# nrf54l15_enga_application register map
Vendor: Nordic Semiconductor; Series: nrf54l; File version: 1
CPU: CM33 r0p4, little endian, MPU, FPU, 3 interrupt priority bits, 270 interrupts, 4 SAU regions
Registers are 32-bit, read-write, reset 0x0 unless marked. A register's access mark holds for its fields unless they carry their own. Offsets are from the block's base; [hi:lo] are bit positions; lines under a group give offsets from that group; {n}, {i} and the like mark numbered series.

## GLOBAL_GLITCHDET_S — Voltage glitch detectors
Base 0x5004B000
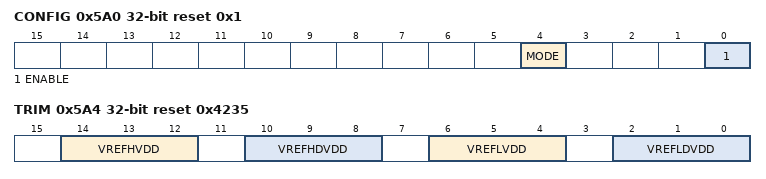
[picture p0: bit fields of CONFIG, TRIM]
0x5A0 CONFIG reset 0x1 — Configuration for glitch detector
  [4] MODE — Glitch detector mode
    0=High pass filter mode; 1=Cap divider mode
  [0] ENABLE — Enable glitch detector
    0=Disable glitch detector; 1=Enable glitch detector
0x5A4 TRIM reset 0x4235 — Trim configuration for glitch detector
  [14:12] VREFHVDD — Voltage trimming value for VREFH_VDD
    0=1V150 (0.150 V); 1=1V175 (0.175 V); 2=1V200 (1.200 V); 3=1V225 (1.225 V); 4=1V250 (1.250 V); 5=1V275 (1.275 V); 6=1V300 (1.300 V); 7=1V325 (1.325 V)
  [10:8] VREFHDVDD — Voltage trimming value for VREFH_DVDD
    0=0V950 (0.950 V); 1=0V975 (0.975 V); 2=1V000 (1.000 V); 3=1V025 (1.025 V); 4=1V050 (1.050 V); 5=1V075 (1.075 V); 6=1V100 (1.100 V); 7=1V125 (1.125 V)
  [6:4] VREFLVDD — Voltage trimming value for VREFL_VDD
    0=0V425 (0.425 V); 1=0V450 (0.450 V); 2=0V475 (0.475 V); 3=0V500 (0.500 V); 4=0V525 (0.525 V); 5=0V550 (0.550 V); 6=0V575 (0.575 V); 7=0V600 (0.600 V)
  [2:0] VREFLDVDD — Voltage trimming value for VREFL_DVDD
    0=0V675 (0.675 V); 1=0V700 (0.700 V); 2=0V725 (0.725 V); 3=0V750 (0.750 V); 4=0V775 (0.775 V); 5=0V800 (0.800 V); 6=0V825 (0.825 V); 7=0V850 (0.850 V)
0x5B0 DFT group — Unspecified
  0x00 ATB0CONFIG — Analog Test Bus 0 (ATB0) configuration
    [2:0] SELMUX — Select multiplexer for ATB0
      0=HiZ (High impedance); 1=VDDDIV (Measure/Force VDD_DIV voltage from external); 2=VDDDIG0V9 (Measure/Force VDD_DIG_0V9 voltage from external); 3=VSS; 4=GLITCHSRVDD3V0 (Internal signal - GLITCH_SR_VDD_3V0)
  0x04 ATB1CONFIG — Analog Test Bus 1 (ATB1) configuration
    [2:0] SELMUX — Select multiplexer for ATB1
      0=HiZ (High impedance); 1=VREFHVDD (Measure VREFH_VDD voltage); 2=VREFLVDD (Measure VREFL_VDD voltage); 3=VREFHDAVDD (Measure VREFH_DVDD voltage); 4=VREFLDVDD (Measure VREFL_DVDD voltage); 5=GLITCHSRDVDD3V0 (Internal signal - GLITCH_SR_DVDD_3V0)
  0x08 ATB2CONFIG — Analog Test Bus 2 (ATB2) configuration
    [1:0] SELMUX — Select multiplexer for ATB2
      0=HiZ (High impedance); 1=VTAMPORDVDD3V0 (Internal signal - VTAMP_OR_DVDD_3V0); 2=VTAMPORVDD3V0 (Internal signal - VTAMP_OR_VDD_3V0); 3=GLITCHNINT3V0 (Internal signal - GLITCH_N_INT_3V0)

## GLOBAL_GPIOHSPADCTRL_NS — GPIO high-speed pad control 0
Base 0x40050400
Same registers: GLOBAL_GPIOHSPADCTRL_S 0x50050400
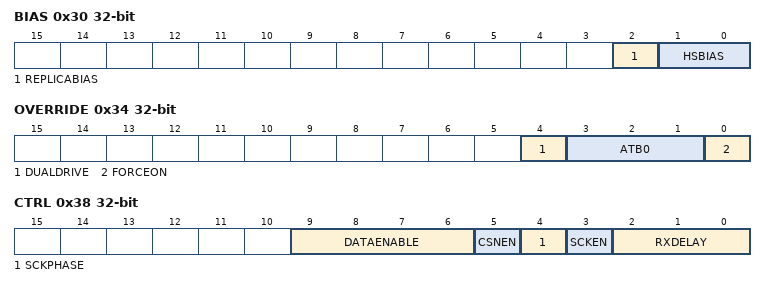
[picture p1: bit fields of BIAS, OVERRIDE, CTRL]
0x30 BIAS — Bias control
  [2] REPLICABIAS — Bias setting for replica pad
  [1:0] HSBIAS — Bias setting for high-speed pad
0x34 OVERRIDE — Override control
  [4] DUALDRIVE — Drive pad from both high-speed pad and regular pad (when highspeed is enabled)
  [3:1] ATB0 — ATB0 settings
    7=BiasTrim (Unspecified); 6=BiasSupply (Unspecified); 5=BiasPTAT (Unspecified)
  [0] FORCEON
0x38 CTRL — HS pad control register
  [9:6] DATAENABLE — Enable re-clocking for data bit 0-3 through pad-sync module
  [5] CSNEN — CSN enable
  [4] SCKPHASE
  [3] SCKEN — Enable SCK
  [2:0] RXDELAY — RXDELAY setting

## GLOBAL_GPIOINTERNALP2_NS — GPIO Internal 0
Base 0x40051E00
Same registers: GLOBAL_GPIOINTERNALP1_NS 0x400D9E00, GLOBAL_GPIOINTERNALP0_NS 0x4010BE00, GLOBAL_GPIOINTERNALP2_S 0x50051E00, GLOBAL_GPIOINTERNALP1_S 0x500D9E00, GLOBAL_GPIOINTERNALP0_S 0x5010BE00
0x40 LATCHCLRWAITCNT reset 0x2 — Select the number of wait cycles inserted on the bus when a LATCH register is cleared.
  [1:0] LATCHCLRWAITCNT
0x44 FORCELDETECTLOWCNT reset 0x8 — Select the number of cycles that LDETECT is forced low after clearing a LATCH register.
  [3:0] FORCELDETECTLOWCNT
0x48 RESET — Reset all GPIO registers.
  [0] RESET
    1=RESET (Trigger reset); 0=NA (No effect)
0x4C SENSECONFIGCHANGECNT reset 0x3 — Selects the number of cycles before the SENSE configuration takes effect when it is changed. Setting this register lower than the reset value can lead to unwanted LATCH set when SENSE and INPUT fields (PIN[n].CNF) are changed simultaneously.
  [2:0] SENSECONFIGCHANGECNT — Selects the number of cycles before the SENSE configuration takes effect when it is changed.
0x160 PCGC group — Unspecified
  {0x20+4j} PENALTY[{j}] (j=0..3) ro — Description collection: Penalty level for power/clock pair n
    [1:0] PENALTY — Penalty level
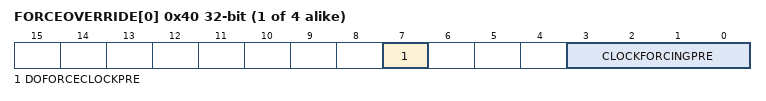
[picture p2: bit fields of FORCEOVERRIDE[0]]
  {0x40+4j} FORCEOVERRIDE[{j}] (j=0..3) ro — Description collection: Force override of power/clock pair n
    [7] DOFORCECLOCKPRE, [3:0] CLOCKFORCINGPRE
